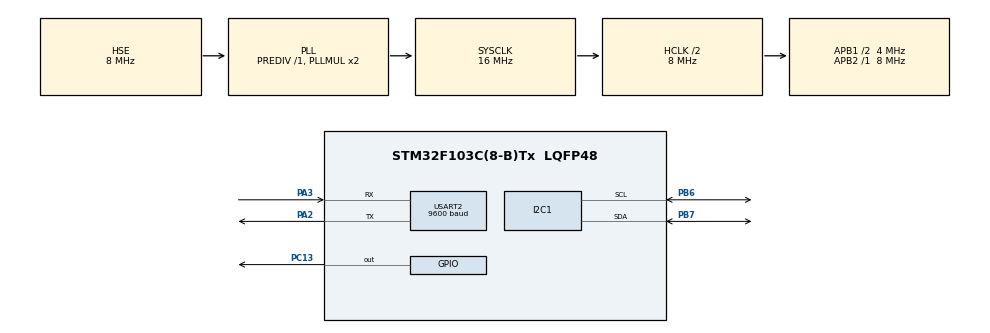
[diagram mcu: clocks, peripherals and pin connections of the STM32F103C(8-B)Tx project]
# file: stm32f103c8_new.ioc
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Mcu.Family=STM32F1
Mcu.Name=STM32F103C(8-B)Tx
Mcu.Package=LQFP48
NVIC.PriorityGroup=NVIC_PRIORITYGROUP_4
PA2.Mode=Asynchronous
PA2.Signal=USART2_TX
PA3.Mode=Asynchronous
PA3.Signal=USART2_RX
PB6.Mode=I2C
PB6.Signal=I2C1_SCL
PB7.Mode=I2C
PB7.Signal=I2C1_SDA
PC13-TAMPER-RTC.Signal=GPIO_Output
PD0-OSC_IN.Mode=HSE-External-Oscillator
PD0-OSC_IN.Signal=RCC_OSC_IN
PD1-OSC_OUT.Mode=HSE-External-Oscillator
PD1-OSC_OUT.Signal=RCC_OSC_OUT
ProjectManager.HeapSize=0x200
ProjectManager.StackSize=0x400
ProjectManager.TargetToolchain=STM32CubeIDE
RCC.AHBCLKDivider=RCC_SYSCLK_DIV2
RCC.AHBFreq_Value=8000000
RCC.APB1CLKDivider=RCC_HCLK_DIV2
RCC.APB1Freq_Value=4000000
RCC.APB1TimFreq_Value=8000000
RCC.APB2Freq_Value=8000000
RCC.APB2TimFreq_Value=8000000
RCC.HCLKFreq_Value=8000000
RCC.PLLSourceVirtual=RCC_PLLSOURCE_HSE
RCC.SYSCLKFreq_VALUE=16000000
RCC.SYSCLKSource=RCC_SYSCLKSOURCE_PLLCLK
RCC.USBFreq_Value=16000000
USART2.BaudRate=9600
USART2.VirtualMode=VM_ASYNC
VP_SYS_VS_ND.Mode=No_Debug
board=custom

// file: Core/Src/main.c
/* USER CODE BEGIN Header */
/**
  ******************************************************************************
  * @file           : main.c
  * @brief          : Main program body
  ******************************************************************************
  * @attention
  *
  * Copyright (c) 2023 STMicroelectronics.
  * All rights reserved.
  *
  * This software is licensed under terms that can be found in the LICENSE file
  * in the root directory of this software component.
  * If no LICENSE file comes with this software, it is provided AS-IS.
  *
  ******************************************************************************
  */
/* USER CODE END Header */
#include "main.h"
#include "i2c.h"
#include "usart.h"
#include "gpio.h"

void SystemClock_Config(void);

int main(void)
{

  /* MCU Configuration--------------------------------------------------------*/

  /* Reset of all peripherals, Initializes the Flash interface and the Systick. */
  HAL_Init();

  /* Configure the system clock */
  SystemClock_Config();

  /* Initialize all configured peripherals */
  MX_GPIO_Init();
  MX_USART2_UART_Init();
  MX_I2C1_Init();
  /* USER CODE BEGIN 2 */
uint8_t buffer[] = "hello___ stm32 \n\r" ;
uint8_t Buffer[5];
 HAL_UART_Transmit(&huart2, buffer, sizeof(buffer), 20);
//uint8_t string_[] = "dsdadasd";
HAL_StatusTypeDef result;

  /* USER CODE END 2 */

  /* Infinite loop */
  while (1)
  {

    /* USER CODE BEGIN 3 */
//	  HAL_GPIO_TogglePin(GPIOB, GPIO_PIN_0);
//	  status__ = HAL_I2C_IsDeviceReady(&hi2c1, i++, 10, 10);
//	  HAL_I2C_Init(&hi2c1);
//	  result = HAL_I2C_IsDeviceReady(&hi2c1, (uint16_t)(i<<1), 2, 2);
//	 	  if (result != HAL_OK) // HAL_ERROR or HAL_BUSY or HAL_TIMEOUT
//	 	  {
//	 		  HAL_GPIO_TogglePin(GPIOB, GPIO_PIN_0);
//	 	  }
//	 	  if (result == HAL_OK)
//	 	  {
//	 		  HAL_GPIO_TogglePin(GPIOB, GPIO_PIN_1);
//	 	  }

//	  status__ = HAL_I2C_Master_Transmit(&hi2c1, i++,(uint8_t*)string_,sizeof(string_), 100);
//	  HAL_I2C_DeInit(&hi2c1);
//	  if (status__ ==HAL_ERROR)
//		  HAL_GPIO_TogglePin(GPIOB, GPIO_PIN_1);
	  	  for (uint8_t i = 0 ; i< 127 ;i++)
	  	  {
	  			 result = HAL_I2C_IsDeviceReady(&hi2c1, (uint16_t)(i<<1), 2, 2);
	  			 if (result != HAL_OK) // HAL_ERROR or HAL_BUSY or HAL_TIMEOUT
				  {
	  				HAL_UART_Transmit(&huart2, (uint8_t*)" -- ", 2, 20);

				  }
				  if (result == HAL_OK)
				  {
					  sprintf(Buffer, "0x%X", i);

		  				HAL_UART_Transmit(&huart2,Buffer , sizeof(Buffer), 20);

	  	  }
	  		  HAL_GPIO_TogglePin(GPIOC, GPIO_PIN_13);
	  HAL_Delay(100);
  }
  /* USER CODE END 3 */
  }}

void SystemClock_Config(void)
{
  RCC_OscInitTypeDef RCC_OscInitStruct = {0};
  RCC_ClkInitTypeDef RCC_ClkInitStruct = {0};

  /** Initializes the RCC Oscillators according to the specified parameters
  * in the RCC_OscInitTypeDef structure.
  */
  RCC_OscInitStruct.OscillatorType = RCC_OSCILLATORTYPE_HSE;
  RCC_OscInitStruct.HSEState = RCC_HSE_ON;
  RCC_OscInitStruct.HSEPredivValue = RCC_HSE_PREDIV_DIV1;
  RCC_OscInitStruct.HSIState = RCC_HSI_ON;
  RCC_OscInitStruct.PLL.PLLState = RCC_PLL_ON;
  RCC_OscInitStruct.PLL.PLLSource = RCC_PLLSOURCE_HSE;
  RCC_OscInitStruct.PLL.PLLMUL = RCC_PLL_MUL2;
  if (HAL_RCC_OscConfig(&RCC_OscInitStruct) != HAL_OK)
  {
    Error_Handler();
  }

  /** Initializes the CPU, AHB and APB buses clocks
  */
  RCC_ClkInitStruct.ClockType = RCC_CLOCKTYPE_HCLK|RCC_CLOCKTYPE_SYSCLK
                              |RCC_CLOCKTYPE_PCLK1|RCC_CLOCKTYPE_PCLK2;
  RCC_ClkInitStruct.SYSCLKSource = RCC_SYSCLKSOURCE_PLLCLK;
  RCC_ClkInitStruct.AHBCLKDivider = RCC_SYSCLK_DIV2;
  RCC_ClkInitStruct.APB1CLKDivider = RCC_HCLK_DIV2;
  RCC_ClkInitStruct.APB2CLKDivider = RCC_HCLK_DIV1;

  if (HAL_RCC_ClockConfig(&RCC_ClkInitStruct, FLASH_LATENCY_0) != HAL_OK)
  {
    Error_Handler();
  }
}

void Error_Handler(void)
{
  __disable_irq();
  while (1)
  {
  }
}
